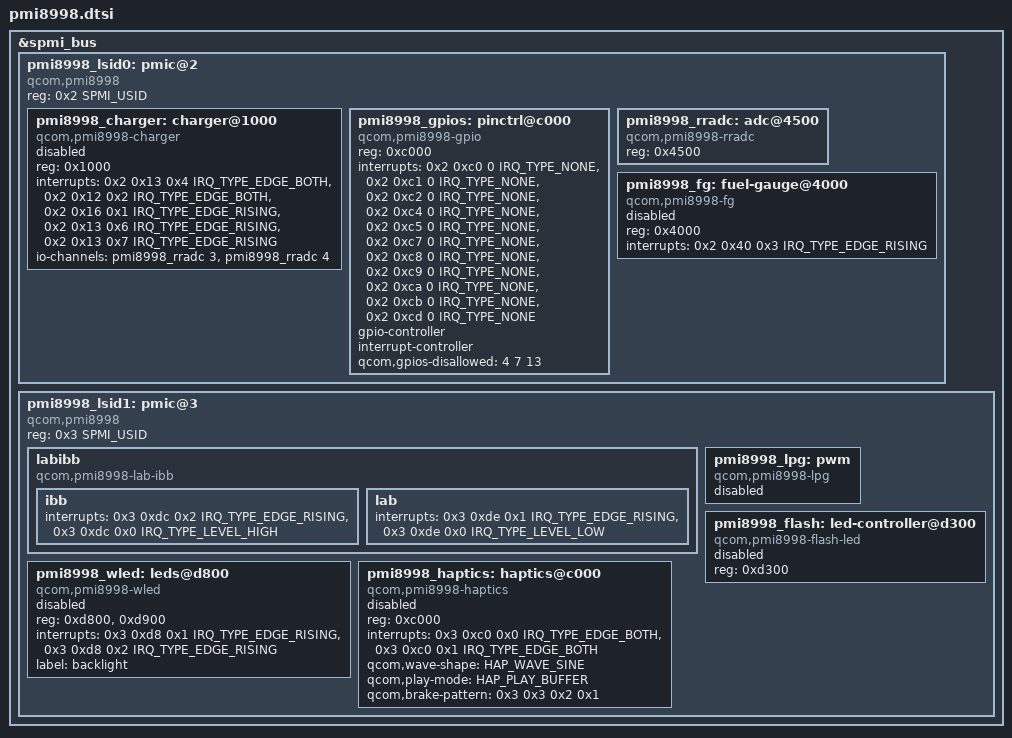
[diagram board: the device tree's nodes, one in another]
// SPDX-License-Identifier: GPL-2.0
#include <dt-bindings/input/qcom,spmi-haptics.h>
#include <dt-bindings/interrupt-controller/irq.h>
#include <dt-bindings/spmi/spmi.h>


&spmi_bus {
	pmi8998_lsid0: pmic@2 {
		compatible = "qcom,pmi8998", "qcom,spmi-pmic";
		reg = <0x2 SPMI_USID>;
		#address-cells = <1>;
		#size-cells = <0>;

		pmi8998_charger: charger@1000 {
			compatible = "qcom,pmi8998-charger";
			reg = <0x1000>;

			interrupts = <0x2 0x13 0x4 IRQ_TYPE_EDGE_BOTH>,
				     <0x2 0x12 0x2 IRQ_TYPE_EDGE_BOTH>,
				     <0x2 0x16 0x1 IRQ_TYPE_EDGE_RISING>,
				     <0x2 0x13 0x6 IRQ_TYPE_EDGE_RISING>,
				     <0x2 0x13 0x7 IRQ_TYPE_EDGE_RISING>;

			interrupt-names = "usb-plugin",
					  "bat-ov",
					  "wdog-bark",
					  "usbin-icl-change",
					  "type-c-change";

			io-channels = <&pmi8998_rradc 3>,
				      <&pmi8998_rradc 4>;
			io-channel-names = "usbin_i", "usbin_v";

			status = "disabled";
		};

/*		pmi8998_gpios: gpio@c000 {
			compatible = "qcom,pmi8998-gpio", "qcom,spmi-gpio";
			reg = <0xc000 0xe00>;
			gpio-controller;
			gpio-ranges = <&pmi8998_gpios 0 0 14>;
			#gpio-cells = <2>;
			interrupt-controller;
			#interrupt-cells = <2>;
		};
*/
		pmi8998_gpios: pinctrl@c000 {
			compatible = "qcom,pmi8998-gpio", "qcom,spmi-gpio";
			reg = <0xc000>;
			interrupts = <0x2 0xc0 0 IRQ_TYPE_NONE>,
					<0x2 0xc1 0 IRQ_TYPE_NONE>,
					<0x2 0xc2 0 IRQ_TYPE_NONE>,
					<0x2 0xc4 0 IRQ_TYPE_NONE>,
					<0x2 0xc5 0 IRQ_TYPE_NONE>,
					<0x2 0xc7 0 IRQ_TYPE_NONE>,
					<0x2 0xc8 0 IRQ_TYPE_NONE>,
					<0x2 0xc9 0 IRQ_TYPE_NONE>,
					<0x2 0xca 0 IRQ_TYPE_NONE>,
					<0x2 0xcb 0 IRQ_TYPE_NONE>,
					<0x2 0xcd 0 IRQ_TYPE_NONE>;
			interrupt-names = "pmi8998_gpio1", "pmi8998_gpio2",
					"pmi8998_gpio3", "pmi8998_gpio5",
					"pmi8998_gpio6", "pmi8998_gpio8",
					"pmi8998_gpio9", "pmi8998_gpio10",
					"pmi8998_gpio11", "pmi8998_gpio12",
					"pmi8998_gpio14";
			gpio-controller;
			#gpio-cells = <2>;
			interrupt-controller;
			#interrupt-cells = <2>;
			qcom,gpios-disallowed = <4 7 13>;
		};
/*
		pmi8998_pdphy: qcom,usb-pdphy@1700 {
			compatible = "qcom,qpnp-pdphy";
			reg = <0x1700 0x100>;
			vdd-pdphy-supply = <&vreg_l24a_3p075>;
			vbus-supply = <&ext_5v_boost>;
			vconn-supply = <&smb2_vconn>;
			interrupts = <0x2 0x17 0x0 IRQ_TYPE_EDGE_RISING>,
				     <0x2 0x17 0x1 IRQ_TYPE_EDGE_RISING>,
				     <0x2 0x17 0x2 IRQ_TYPE_EDGE_RISING>,
				     <0x2 0x17 0x3 IRQ_TYPE_EDGE_RISING>,
				     <0x2 0x17 0x4 IRQ_TYPE_EDGE_RISING>,
				     <0x2 0x17 0x5 IRQ_TYPE_EDGE_RISING>,
				     <0x2 0x17 0x6 IRQ_TYPE_EDGE_RISING>;

			interrupt-names = "sig-tx",
					  "sig-rx",
					  "msg-tx",
					  "msg-rx",
					  "msg-tx-failed",
					  "msg-tx-discarded",
					  "msg-rx-discarded";

			qcom,default-sink-caps = <5000 3000>, // 5V @ 3A
						 <9000 3000>, // 9V @ 3A
						 <12000 2250>; // 12V @ 2.25A

			status = "disabled";
		};
		*/
		pmi8998_rradc: adc@4500 {
			compatible = "qcom,pmi8998-rradc";
			reg = <0x4500>;
			#io-channel-cells = <1>;
		};

		pmi8998_fg: fuel-gauge@4000 {
			compatible = "qcom,pmi8998-fg";
			reg = <0x4000>;

			interrupts = <0x2 0x40 0x3 IRQ_TYPE_EDGE_RISING>;
			interrupt-names = "soc-delta";

			status = "disabled";
		};

	};

	pmi8998_lsid1: pmic@3 {
		compatible = "qcom,pmi8998", "qcom,spmi-pmic";
		reg = <0x3 SPMI_USID>;
		#address-cells = <1>;
		#size-cells = <0>;

		labibb {
			compatible = "qcom,pmi8998-lab-ibb";

			ibb: ibb {
				interrupts = <0x3 0xdc 0x2 IRQ_TYPE_EDGE_RISING>,
					     <0x3 0xdc 0x0 IRQ_TYPE_LEVEL_HIGH>;
				interrupt-names = "sc-err", "ocp";
			};

			lab: lab {
				interrupts = <0x3 0xde 0x1 IRQ_TYPE_EDGE_RISING>,
					     <0x3 0xde 0x0 IRQ_TYPE_LEVEL_LOW>;
				interrupt-names = "sc-err", "ocp";
			};
		};

		pmi8998_lpg: pwm {
			compatible = "qcom,pmi8998-lpg";

			#address-cells = <1>;
			#size-cells = <0>;
			#pwm-cells = <2>;

			status = "disabled";
		};

		pmi8998_flash: led-controller@d300 {
			compatible = "qcom,pmi8998-flash-led", "qcom,spmi-flash-led";
			reg = <0xd300>;
			status = "disabled";
		};

		pmi8998_wled: leds@d800 {
			compatible = "qcom,pmi8998-wled";
			reg = <0xd800>, <0xd900>;
			interrupts = <0x3 0xd8 0x1 IRQ_TYPE_EDGE_RISING>,
				     <0x3 0xd8 0x2 IRQ_TYPE_EDGE_RISING>;
			interrupt-names = "ovp", "short";
			label = "backlight";

			status = "disabled";
		};

		pmi8998_haptics: haptics@c000 {
			compatible = "qcom,pmi8998-haptics", "qcom,spmi-haptics";
			reg = <0xc000>;

			interrupts = <0x3 0xc0 0x0 IRQ_TYPE_EDGE_BOTH>,
				     <0x3 0xc0 0x1 IRQ_TYPE_EDGE_BOTH>;
			interrupt-names = "short", "play";

			qcom,wave-shape = <HAP_WAVE_SINE>;
			qcom,play-mode = <HAP_PLAY_BUFFER>;
			qcom,brake-pattern = <0x3 0x3 0x2 0x1>;

			status = "disabled";
		};
	};
};
